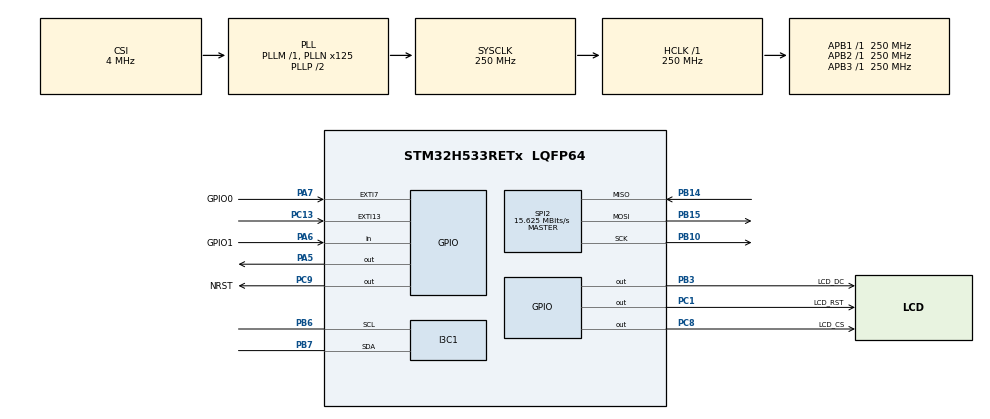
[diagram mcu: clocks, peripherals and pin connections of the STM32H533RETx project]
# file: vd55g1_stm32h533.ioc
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BOOTPATH.BootPathName=LEGACY
BOOTPATH.UserSelectedBootPath=LEGACY
CORTEX_M33_NS.userName=CORTEX_M33
GPDMA1.DESTDATAWIDTH_GPDMACH0=DMA_DEST_DATAWIDTH_WORD
GPDMA1.DESTINC_GPDMACH2=DMA_DINC_INCREMENTED
GPDMA1.IPHANDLE_GPDMACH0-SIMPLEREQUEST_GPDMACH0=__NULL
GPDMA1.IPHANDLE_GPDMACH1-SIMPLEREQUEST_GPDMACH1=__NULL
GPDMA1.IPHANDLE_GPDMACH2-SIMPLEREQUEST_GPDMACH2=__NULL
GPDMA1.REQUEST_GPDMACH0=GPDMA1_REQUEST_I3C1_TC
GPDMA1.REQUEST_GPDMACH1=GPDMA1_REQUEST_I3C1_TX
GPDMA1.REQUEST_GPDMACH2=GPDMA1_REQUEST_I3C1_RX
GPDMA1.SRCDATAWIDTH_GPDMACH0=DMA_SRC_DATAWIDTH_WORD
GPDMA1.SRCINC_GPDMACH0=DMA_SINC_INCREMENTED
GPDMA1.SRCINC_GPDMACH1=DMA_SINC_INCREMENTED
I3C1.BusFreeDuration=98
I3C1.DutyCycleI3C=50
I3C1.FrequencyI3C=1000
I3C1.Register0=0x007c7c7c
I3C1.Register1=0x100c00f8
I3C1.SCLI3CHighDuration=0x7c
I3C1.SCLODLowDuration=0x7c
I3C1.SCLPPLowDuration=0x7c
I3C1.SCL_OD_Freq=1000
I3C1.SCL_PP_Freq=1000
I3C1.SDAHoldTime=HAL_I3C_SDA_HOLD_TIME_1_5
I3C1.SDARiseTime=50
I3C1.hexBusFreeDuration=0x0c
I3C1.hexBusIdleDuration=0xf8
Mcu.Family=STM32H5
Mcu.Name=STM32H533RETx
Mcu.Package=LQFP64
NUCLEO-H533RE.BUTTON=1
NUCLEO-H533RE.LD4=true
NUCLEO-H533RE.VCP=true
NVIC.EXTI13_IRQn=true\:0\:0\:false\:false\:true\:false\:true\:true
NVIC.EXTI7_IRQn=true\:0\:0\:false\:false\:true\:true\:true\:true
NVIC.GPDMA1_Channel0_IRQn=true\:0\:0\:false\:false\:true\:false\:true\:true
NVIC.GPDMA1_Channel1_IRQn=true\:0\:0\:false\:false\:true\:false\:true\:true
NVIC.GPDMA1_Channel2_IRQn=true\:0\:0\:false\:false\:true\:false\:true\:true
NVIC.I3C1_ER_IRQn=true\:0\:0\:false\:false\:true\:true\:true\:true
NVIC.I3C1_EV_IRQn=true\:0\:0\:false\:false\:true\:true\:true\:true
NVIC.PriorityGroup=NVIC_PRIORITYGROUP_4
NVIC.SPI2_IRQn=true\:0\:0\:false\:false\:true\:true\:true\:true
PA13(JTMS/SWDIO).GPIO_Label=SWDIO
PA13(JTMS/SWDIO).Signal=DEBUG_JTMS-SWDIO
PA14(JTCK/SWCLK).GPIO_Label=SWCLK
PA14(JTCK/SWCLK).Signal=DEBUG_JTCK-SWCLK
PA15(JTDI).GPIO_Label=JTDI
PA15(JTDI).Signal=DEBUG_JTDI
PA2.Signal=USART2_TX
PA3.Signal=USART2_RX
PA5.Signal=GPIO_Output
PA6.GPIO_Label=GPIO1
PA6.Signal=GPIO_Input
PA7.GPIO_Label=GPIO0
PA7.Signal=GPXTI7
PB10.Mode=Full_Duplex_Master
PB10.Signal=SPI2_SCK
PB14.Mode=Full_Duplex_Master
PB14.Signal=SPI2_MISO
PB15.Mode=Full_Duplex_Master
PB15.Signal=SPI2_MOSI
PB3(JTDO/TRACESWO).GPIO_Label=LCD_DC
PB3(JTDO/TRACESWO).Signal=GPIO_Output
PB6.Mode=Controller
PB6.Signal=I3C1_SCL
PB7.Mode=Controller
PB7.Signal=I3C1_SDA
PC1.GPIO_Label=LCD_RST
PC1.Signal=GPIO_Output
PC13.Signal=GPXTI13
PC8.GPIO_Label=LCD_CS
PC8.Signal=GPIO_Output
PC9.GPIO_Label=NRST
PC9.GPIO_ModeDefaultOutputPP=GPIO_MODE_OUTPUT_OD
PC9.GPIO_PuPd=GPIO_PULLUP
PC9.PinState=GPIO_PIN_SET
PC9.Signal=GPIO_Output
ProjectManager.HeapSize=0x200
ProjectManager.StackSize=0x400
ProjectManager.TargetToolchain=STM32CubeIDE
RCC.ADCFreq_Value=250000000
RCC.AHBFreq_Value=250000000
RCC.APB1Freq_Value=250000000
RCC.APB1TimFreq_Value=250000000
RCC.APB2Freq_Value=250000000
RCC.APB2TimFreq_Value=250000000
RCC.APB3Freq_Value=250000000
RCC.CSI_VALUE=4000000
RCC.CortexFreq_Value=250000000
RCC.EPOD_VALUE=4000000
RCC.HCLKFreq_Value=250000000
RCC.HSE_VALUE=25000000
RCC.HSI48_VALUE=48000000
RCC.HSIDiv=RCC_HSI_DIV1
RCC.HSI_VALUE=64000000
RCC.LSE_VALUE=32768
RCC.LSIRC_VALUE=32000
RCC.PLLN=125
RCC.SYSCLKFreq_VALUE=250000000
RCC.SYSCLKSource=RCC_SYSCLKSOURCE_PLLCLK
RCC.USBFreq_Value=48000000
RCC.VCOOutputFreq_Value=500000000
SPI2.BaudRatePrescaler=SPI_BAUDRATEPRESCALER_16
SPI2.CalculateBaudRate=15.625 MBits/s
SPI2.DataSize=SPI_DATASIZE_8BIT
SPI2.Direction=SPI_DIRECTION_2LINES
SPI2.Mode=SPI_MODE_MASTER
SPI2.VirtualType=VM_MASTER
VP_BOOTPATH_VS_BOOTPATH.Mode=BP_Activate
VP_CORTEX_M33_NS_VS_Hclk.Mode=Hclk_Mode
VP_GPDMA1_VS_GPDMACH0.Mode=SIMPLEREQUEST_GPDMACH0
VP_GPDMA1_VS_GPDMACH1.Mode=SIMPLEREQUEST_GPDMACH1
VP_GPDMA1_VS_GPDMACH2.Mode=SIMPLEREQUEST_GPDMACH2
VP_ICACHE_VS_ENABLE_ICACHE_MEMORY.Mode=Memoryregions
VP_ICACHE_VS_ICACHE.Mode=DefaultMode
VP_MEMORYMAP_VS_MEMORYMAP.Mode=CurAppReg
VP_NUCLEO-H533RE_VS_BSP_COMMON.Mode=COMMON
VP_PWR_VS_DBSignals.Mode=DisableDeadBatterySignals
VP_PWR_VS_LPOM.Mode=PowerOptimisation
VP_PWR_VS_SECSignals.Mode=Security/Privilege
board=NUCLEO-H533RE

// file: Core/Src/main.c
/* USER CODE BEGIN Header */
/**
  ******************************************************************************
  * @file           : main.c
  * @brief          : Main program body
  ******************************************************************************
  * @attention
  *
  * Copyright (c) 2025 STMicroelectronics.
  * All rights reserved.
  *
  * This software is licensed under terms that can be found in the LICENSE file
  * in the root directory of this software component.
  * If no LICENSE file comes with this software, it is provided AS-IS.
  *
  ******************************************************************************
  */
/* USER CODE END Header */
#include "main.h"

/* USER CODE BEGIN Includes */
#include "stm32h5xx_hal.h"
#include "stm32h5xx.h"
#include <stdint.h>
#include <sys/types.h>
#include <string.h> // Include for memset

#include "ls55g1_app.h"
/* USER CODE END Includes */

COM_InitTypeDef BspCOMInit;

I3C_HandleTypeDef hi3c1;
DMA_HandleTypeDef handle_GPDMA1_Channel2;
DMA_HandleTypeDef handle_GPDMA1_Channel1;
DMA_HandleTypeDef handle_GPDMA1_Channel0;

SPI_HandleTypeDef hspi2;

void SystemClock_Config(void);
static void MX_GPDMA1_Init(void);
static void MX_GPIO_Init(void);
static void MX_ICACHE_Init(void);
static void MX_I3C1_Init(void);
static void MX_SPI2_Init(void);

int main(void)
{

  /* MCU Configuration--------------------------------------------------------*/

  /* Reset of all peripherals, Initializes the Flash interface and the Systick. */
  HAL_Init();

  /* Configure the system clock */
  SystemClock_Config();

  /* Initialize all configured peripherals */
  MX_GPDMA1_Init();
  MX_GPIO_Init();
  MX_ICACHE_Init();
  MX_I3C1_Init();
  MX_SPI2_Init();

  /* Initialize leds */
  BSP_LED_Init(LED_GREEN);

  /* Initialize USER push-button, will be used to trigger an interrupt each time it's pressed.*/
  BSP_PB_Init(BUTTON_USER, BUTTON_MODE_EXTI);

  /* Initialize COM1 port (115200, 8 bits (7-bit data + 1 stop bit), no parity */
  BspCOMInit.BaudRate   = 115200;
  BspCOMInit.WordLength = COM_WORDLENGTH_8B;
  BspCOMInit.StopBits   = COM_STOPBITS_1;
  BspCOMInit.Parity     = COM_PARITY_NONE;
  BspCOMInit.HwFlowCtl  = COM_HWCONTROL_NONE;
  if (BSP_COM_Init(COM1, &BspCOMInit) != BSP_ERROR_NONE)
  {
    Error_Handler();
  }

  /* Infinite loop */
  /* USER CODE BEGIN WHILE */
  ls55g1_setup();

  while (1)
  {

	ls55g1_main();
    /* USER CODE END WHILE */

  }
}

void SystemClock_Config(void)
{
  RCC_OscInitTypeDef RCC_OscInitStruct = {0};
  RCC_ClkInitTypeDef RCC_ClkInitStruct = {0};

  /** Configure the main internal regulator output voltage
  */
  __HAL_PWR_VOLTAGESCALING_CONFIG(PWR_REGULATOR_VOLTAGE_SCALE0);

  while(!__HAL_PWR_GET_FLAG(PWR_FLAG_VOSRDY)) {}

  /** Initializes the RCC Oscillators according to the specified parameters
  * in the RCC_OscInitTypeDef structure.
  */
  RCC_OscInitStruct.OscillatorType = RCC_OSCILLATORTYPE_CSI;
  RCC_OscInitStruct.CSIState = RCC_CSI_ON;
  RCC_OscInitStruct.CSICalibrationValue = RCC_CSICALIBRATION_DEFAULT;
  RCC_OscInitStruct.PLL.PLLState = RCC_PLL_ON;
  RCC_OscInitStruct.PLL.PLLSource = RCC_PLL1_SOURCE_CSI;
  RCC_OscInitStruct.PLL.PLLM = 1;
  RCC_OscInitStruct.PLL.PLLN = 125;
  RCC_OscInitStruct.PLL.PLLP = 2;
  RCC_OscInitStruct.PLL.PLLQ = 2;
  RCC_OscInitStruct.PLL.PLLR = 2;
  RCC_OscInitStruct.PLL.PLLRGE = RCC_PLL1_VCIRANGE_2;
  RCC_OscInitStruct.PLL.PLLVCOSEL = RCC_PLL1_VCORANGE_WIDE;
  RCC_OscInitStruct.PLL.PLLFRACN = 0;
  if (HAL_RCC_OscConfig(&RCC_OscInitStruct) != HAL_OK)
  {
    Error_Handler();
  }

  /** Initializes the CPU, AHB and APB buses clocks
  */
  RCC_ClkInitStruct.ClockType = RCC_CLOCKTYPE_HCLK|RCC_CLOCKTYPE_SYSCLK
                              |RCC_CLOCKTYPE_PCLK1|RCC_CLOCKTYPE_PCLK2
                              |RCC_CLOCKTYPE_PCLK3;
  RCC_ClkInitStruct.SYSCLKSource = RCC_SYSCLKSOURCE_PLLCLK;
  RCC_ClkInitStruct.AHBCLKDivider = RCC_SYSCLK_DIV1;
  RCC_ClkInitStruct.APB1CLKDivider = RCC_HCLK_DIV1;
  RCC_ClkInitStruct.APB2CLKDivider = RCC_HCLK_DIV1;
  RCC_ClkInitStruct.APB3CLKDivider = RCC_HCLK_DIV1;

  if (HAL_RCC_ClockConfig(&RCC_ClkInitStruct, FLASH_LATENCY_5) != HAL_OK)
  {
    Error_Handler();
  }

  /** Configure the programming delay
  */
  __HAL_FLASH_SET_PROGRAM_DELAY(FLASH_PROGRAMMING_DELAY_2);
}

static void MX_GPDMA1_Init(void)
{

  /* Peripheral clock enable */
  __HAL_RCC_GPDMA1_CLK_ENABLE();

  /* GPDMA1 interrupt Init */
    HAL_NVIC_SetPriority(GPDMA1_Channel0_IRQn, 0, 0);
    HAL_NVIC_EnableIRQ(GPDMA1_Channel0_IRQn);
    HAL_NVIC_SetPriority(GPDMA1_Channel1_IRQn, 0, 0);
    HAL_NVIC_EnableIRQ(GPDMA1_Channel1_IRQn);
    HAL_NVIC_SetPriority(GPDMA1_Channel2_IRQn, 0, 0);
    HAL_NVIC_EnableIRQ(GPDMA1_Channel2_IRQn);

}

static void MX_I3C1_Init(void)
{

  I3C_FifoConfTypeDef sFifoConfig = {0};
  I3C_CtrlConfTypeDef sCtrlConfig = {0};

  hi3c1.Instance = I3C1;
  hi3c1.Mode = HAL_I3C_MODE_CONTROLLER;
  hi3c1.Init.CtrlBusCharacteristic.SDAHoldTime = HAL_I3C_SDA_HOLD_TIME_1_5;
  hi3c1.Init.CtrlBusCharacteristic.WaitTime = HAL_I3C_OWN_ACTIVITY_STATE_0;
  hi3c1.Init.CtrlBusCharacteristic.SCLPPLowDuration = 0x7c;
  hi3c1.Init.CtrlBusCharacteristic.SCLI3CHighDuration = 0x7c;
  hi3c1.Init.CtrlBusCharacteristic.SCLODLowDuration = 0x7c;
  hi3c1.Init.CtrlBusCharacteristic.SCLI2CHighDuration = 0x00;
  hi3c1.Init.CtrlBusCharacteristic.BusFreeDuration = 0x0c;
  hi3c1.Init.CtrlBusCharacteristic.BusIdleDuration = 0xf8;
  if (HAL_I3C_Init(&hi3c1) != HAL_OK)
  {
    Error_Handler();
  }

  /** Configure FIFO
  */
  sFifoConfig.RxFifoThreshold = HAL_I3C_RXFIFO_THRESHOLD_1_4;
  sFifoConfig.TxFifoThreshold = HAL_I3C_TXFIFO_THRESHOLD_1_4;
  sFifoConfig.ControlFifo = HAL_I3C_CONTROLFIFO_DISABLE;
  sFifoConfig.StatusFifo = HAL_I3C_STATUSFIFO_DISABLE;
  if (HAL_I3C_SetConfigFifo(&hi3c1, &sFifoConfig) != HAL_OK)
  {
    Error_Handler();
  }

  /** Configure controller
  */
  sCtrlConfig.DynamicAddr = 0;
  sCtrlConfig.StallTime = 0x00;
  sCtrlConfig.HotJoinAllowed = DISABLE;
  sCtrlConfig.ACKStallState = DISABLE;
  sCtrlConfig.CCCStallState = DISABLE;
  sCtrlConfig.TxStallState = DISABLE;
  sCtrlConfig.RxStallState = DISABLE;
  sCtrlConfig.HighKeeperSDA = DISABLE;
  if (HAL_I3C_Ctrl_Config(&hi3c1, &sCtrlConfig) != HAL_OK)
  {
    Error_Handler();
  }

}

static void MX_ICACHE_Init(void)
{

  /** Enable instruction cache (default 2-ways set associative cache)
  */
  if (HAL_ICACHE_Enable() != HAL_OK)
  {
    Error_Handler();
  }

}

static void MX_SPI2_Init(void)
{

  /* SPI2 parameter configuration*/
  hspi2.Instance = SPI2;
  hspi2.Init.Mode = SPI_MODE_MASTER;
  hspi2.Init.Direction = SPI_DIRECTION_2LINES;
  hspi2.Init.DataSize = SPI_DATASIZE_8BIT;
  hspi2.Init.CLKPolarity = SPI_POLARITY_LOW;
  hspi2.Init.CLKPhase = SPI_PHASE_1EDGE;
  hspi2.Init.NSS = SPI_NSS_SOFT;
  hspi2.Init.BaudRatePrescaler = SPI_BAUDRATEPRESCALER_16;
  hspi2.Init.FirstBit = SPI_FIRSTBIT_MSB;
  hspi2.Init.TIMode = SPI_TIMODE_DISABLE;
  hspi2.Init.CRCCalculation = SPI_CRCCALCULATION_DISABLE;
  hspi2.Init.CRCPolynomial = 0x7;
  hspi2.Init.NSSPMode = SPI_NSS_PULSE_ENABLE;
  hspi2.Init.NSSPolarity = SPI_NSS_POLARITY_LOW;
  hspi2.Init.FifoThreshold = SPI_FIFO_THRESHOLD_01DATA;
  hspi2.Init.MasterSSIdleness = SPI_MASTER_SS_IDLENESS_00CYCLE;
  hspi2.Init.MasterInterDataIdleness = SPI_MASTER_INTERDATA_IDLENESS_00CYCLE;
  hspi2.Init.MasterReceiverAutoSusp = SPI_MASTER_RX_AUTOSUSP_DISABLE;
  hspi2.Init.MasterKeepIOState = SPI_MASTER_KEEP_IO_STATE_DISABLE;
  hspi2.Init.IOSwap = SPI_IO_SWAP_DISABLE;
  hspi2.Init.ReadyMasterManagement = SPI_RDY_MASTER_MANAGEMENT_INTERNALLY;
  hspi2.Init.ReadyPolarity = SPI_RDY_POLARITY_HIGH;
  if (HAL_SPI_Init(&hspi2) != HAL_OK)
  {
    Error_Handler();
  }

}

static void MX_GPIO_Init(void)
{
  GPIO_InitTypeDef GPIO_InitStruct = {0};

  /* GPIO Ports Clock Enable */
  __HAL_RCC_GPIOC_CLK_ENABLE();
  __HAL_RCC_GPIOA_CLK_ENABLE();
  __HAL_RCC_GPIOB_CLK_ENABLE();

  /*Configure GPIO pin Output Level */
  HAL_GPIO_WritePin(GPIOC, LCD_RST_Pin|LCD_CS_Pin, GPIO_PIN_RESET);

  /*Configure GPIO pin Output Level */
  HAL_GPIO_WritePin(NRST_GPIO_Port, NRST_Pin, GPIO_PIN_SET);

  /*Configure GPIO pin Output Level */
  HAL_GPIO_WritePin(LCD_DC_GPIO_Port, LCD_DC_Pin, GPIO_PIN_RESET);

  /*Configure GPIO pins : LCD_RST_Pin LCD_CS_Pin */
  GPIO_InitStruct.Pin = LCD_RST_Pin|LCD_CS_Pin;
  GPIO_InitStruct.Mode = GPIO_MODE_OUTPUT_PP;
  GPIO_InitStruct.Pull = GPIO_NOPULL;
  GPIO_InitStruct.Speed = GPIO_SPEED_FREQ_LOW;
  HAL_GPIO_Init(GPIOC, &GPIO_InitStruct);

  /*Configure GPIO pin : GPIO1_Pin */
  GPIO_InitStruct.Pin = GPIO1_Pin;
  GPIO_InitStruct.Mode = GPIO_MODE_INPUT;
  GPIO_InitStruct.Pull = GPIO_NOPULL;
  HAL_GPIO_Init(GPIO1_GPIO_Port, &GPIO_InitStruct);

  /*Configure GPIO pin : GPIO0_Pin */
  GPIO_InitStruct.Pin = GPIO0_Pin;
  GPIO_InitStruct.Mode = GPIO_MODE_IT_RISING;
  GPIO_InitStruct.Pull = GPIO_NOPULL;
  HAL_GPIO_Init(GPIO0_GPIO_Port, &GPIO_InitStruct);

  /*Configure GPIO pin : NRST_Pin */
  GPIO_InitStruct.Pin = NRST_Pin;
  GPIO_InitStruct.Mode = GPIO_MODE_OUTPUT_OD;
  GPIO_InitStruct.Pull = GPIO_PULLUP;
  GPIO_InitStruct.Speed = GPIO_SPEED_FREQ_LOW;
  HAL_GPIO_Init(NRST_GPIO_Port, &GPIO_InitStruct);

  /*Configure GPIO pin : LCD_DC_Pin */
  GPIO_InitStruct.Pin = LCD_DC_Pin;
  GPIO_InitStruct.Mode = GPIO_MODE_OUTPUT_PP;
  GPIO_InitStruct.Pull = GPIO_NOPULL;
  GPIO_InitStruct.Speed = GPIO_SPEED_FREQ_LOW;
  HAL_GPIO_Init(LCD_DC_GPIO_Port, &GPIO_InitStruct);

  /* EXTI interrupt init*/
  HAL_NVIC_SetPriority(EXTI7_IRQn, 0, 0);
  HAL_NVIC_EnableIRQ(EXTI7_IRQn);

}

void Error_Handler(void)
{
  /* USER CODE BEGIN Error_Handler_Debug */
  /* User can add his own implementation to report the HAL error return state */
  printf("Error_Handler\n");
  __disable_irq();
  while (1)
  {
  }
  /* USER CODE END Error_Handler_Debug */
}
